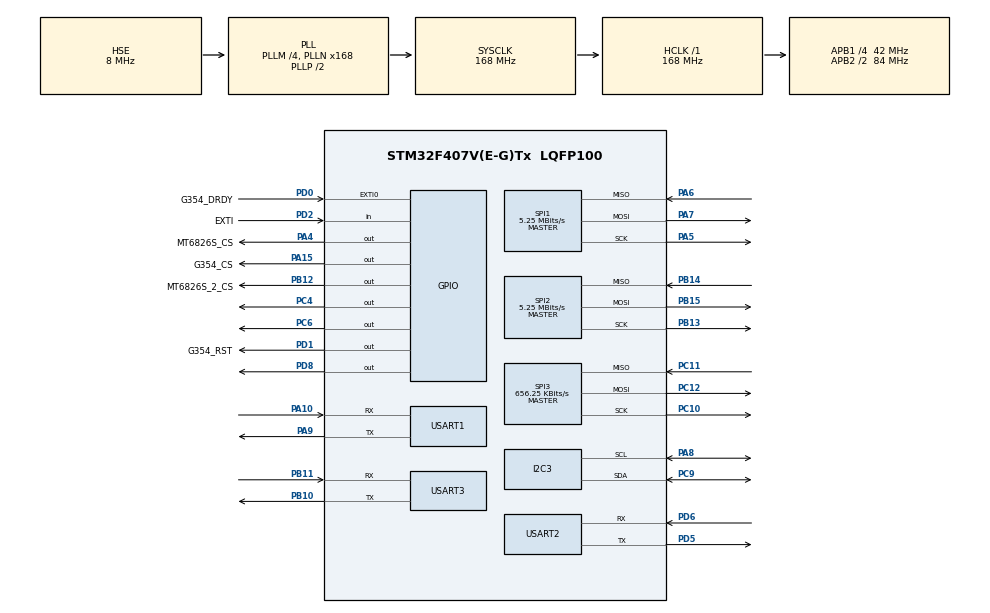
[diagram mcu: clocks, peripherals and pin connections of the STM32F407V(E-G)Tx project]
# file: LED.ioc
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Dma.Request0=SPI1_RX
Dma.Request1=SPI1_TX
Dma.Request2=SPI2_RX
Dma.Request3=SPI2_TX
Dma.Request4=USART2_TX
Dma.SPI1_RX.0.Direction=DMA_PERIPH_TO_MEMORY
Dma.SPI1_RX.0.FIFOMode=DMA_FIFOMODE_DISABLE
Dma.SPI1_RX.0.Instance=DMA2_Stream0
Dma.SPI1_RX.0.MemDataAlignment=DMA_MDATAALIGN_BYTE
Dma.SPI1_RX.0.MemInc=DMA_MINC_ENABLE
Dma.SPI1_RX.0.Mode=DMA_NORMAL
Dma.SPI1_RX.0.PeriphDataAlignment=DMA_PDATAALIGN_BYTE
Dma.SPI1_RX.0.PeriphInc=DMA_PINC_DISABLE
Dma.SPI1_RX.0.Priority=DMA_PRIORITY_HIGH
Dma.SPI1_TX.1.Direction=DMA_MEMORY_TO_PERIPH
Dma.SPI1_TX.1.FIFOMode=DMA_FIFOMODE_DISABLE
Dma.SPI1_TX.1.Instance=DMA2_Stream3
Dma.SPI1_TX.1.MemDataAlignment=DMA_MDATAALIGN_BYTE
Dma.SPI1_TX.1.MemInc=DMA_MINC_ENABLE
Dma.SPI1_TX.1.Mode=DMA_NORMAL
Dma.SPI1_TX.1.PeriphDataAlignment=DMA_PDATAALIGN_BYTE
Dma.SPI1_TX.1.PeriphInc=DMA_PINC_DISABLE
Dma.SPI1_TX.1.Priority=DMA_PRIORITY_HIGH
Dma.SPI2_RX.2.Direction=DMA_PERIPH_TO_MEMORY
Dma.SPI2_RX.2.FIFOMode=DMA_FIFOMODE_DISABLE
Dma.SPI2_RX.2.Instance=DMA1_Stream3
Dma.SPI2_RX.2.MemDataAlignment=DMA_MDATAALIGN_BYTE
Dma.SPI2_RX.2.MemInc=DMA_MINC_ENABLE
Dma.SPI2_RX.2.Mode=DMA_NORMAL
Dma.SPI2_RX.2.PeriphDataAlignment=DMA_PDATAALIGN_BYTE
Dma.SPI2_RX.2.PeriphInc=DMA_PINC_DISABLE
Dma.SPI2_RX.2.Priority=DMA_PRIORITY_HIGH
Dma.SPI2_TX.3.Direction=DMA_MEMORY_TO_PERIPH
Dma.SPI2_TX.3.FIFOMode=DMA_FIFOMODE_DISABLE
Dma.SPI2_TX.3.Instance=DMA1_Stream4
Dma.SPI2_TX.3.MemDataAlignment=DMA_MDATAALIGN_BYTE
Dma.SPI2_TX.3.MemInc=DMA_MINC_ENABLE
Dma.SPI2_TX.3.Mode=DMA_NORMAL
Dma.SPI2_TX.3.PeriphDataAlignment=DMA_PDATAALIGN_BYTE
Dma.SPI2_TX.3.PeriphInc=DMA_PINC_DISABLE
Dma.SPI2_TX.3.Priority=DMA_PRIORITY_HIGH
Dma.USART2_TX.4.Direction=DMA_MEMORY_TO_PERIPH
Dma.USART2_TX.4.FIFOMode=DMA_FIFOMODE_DISABLE
Dma.USART2_TX.4.Instance=DMA1_Stream6
Dma.USART2_TX.4.MemDataAlignment=DMA_MDATAALIGN_BYTE
Dma.USART2_TX.4.MemInc=DMA_MINC_ENABLE
Dma.USART2_TX.4.Mode=DMA_NORMAL
Dma.USART2_TX.4.PeriphDataAlignment=DMA_PDATAALIGN_BYTE
Dma.USART2_TX.4.PeriphInc=DMA_PINC_DISABLE
Dma.USART2_TX.4.Priority=DMA_PRIORITY_MEDIUM
FREERTOS.INCLUDE_uxTaskGetStackHighWaterMark=1
FREERTOS.INCLUDE_vTaskDelayUntil=1
FREERTOS.Tasks01=defaultTask,0,256,StartDefaultTask,Default,NULL,Dynamic,NULL,NULL;imuTask,1,1024,StartimuTask02,Default,NULL,Dynamic,NULL,NULL
FREERTOS.configTOTAL_HEAP_SIZE=20480
Mcu.Family=STM32F4
Mcu.Name=STM32F407V(E-G)Tx
Mcu.Package=LQFP100
NVIC.DMA1_Stream3_IRQn=true\:6\:0\:true\:false\:true\:true\:false\:true\:true
NVIC.DMA1_Stream4_IRQn=true\:6\:0\:true\:false\:true\:true\:false\:true\:true
NVIC.DMA1_Stream6_IRQn=true\:6\:0\:true\:false\:true\:true\:false\:true\:true
NVIC.DMA2_Stream0_IRQn=true\:6\:0\:true\:false\:true\:true\:false\:true\:true
NVIC.DMA2_Stream3_IRQn=true\:6\:0\:true\:false\:true\:true\:false\:true\:true
NVIC.EXTI0_IRQn=true\:5\:0\:false\:false\:true\:true\:true\:true\:true
NVIC.PriorityGroup=NVIC_PRIORITYGROUP_4
NVIC.SPI1_IRQn=true\:5\:0\:false\:false\:true\:true\:true\:true\:true
NVIC.SPI2_IRQn=true\:5\:0\:false\:false\:true\:true\:true\:true\:true
NVIC.TIM6_DAC_IRQn=true\:15\:0\:false\:false\:true\:false\:false\:true\:true
NVIC.TimeBase=TIM6_DAC_IRQn
NVIC.TimeBaseIP=TIM6
NVIC.USART2_IRQn=true\:6\:0\:true\:false\:true\:true\:true\:true\:true
PA10.Mode=Asynchronous
PA10.Signal=USART1_RX
PA13.Mode=Serial_Wire
PA13.Signal=SYS_JTMS-SWDIO
PA14.Mode=Serial_Wire
PA14.Signal=SYS_JTCK-SWCLK
PA15.GPIO_Label=G354_CS
PA15.GPIO_Speed=GPIO_SPEED_FREQ_HIGH
PA15.PinState=GPIO_PIN_SET
PA15.Signal=GPIO_Output
PA4.GPIO_Label=MT6826S_CS
PA4.GPIO_Speed=GPIO_SPEED_FREQ_HIGH
PA4.PinState=GPIO_PIN_SET
PA4.Signal=GPIO_Output
PA5.Mode=Full_Duplex_Master
PA5.Signal=SPI1_SCK
PA6.Mode=Full_Duplex_Master
PA6.Signal=SPI1_MISO
PA7.Mode=Full_Duplex_Master
PA7.Signal=SPI1_MOSI
PA8.Mode=I2C
PA8.Signal=I2C3_SCL
PA9.Mode=Asynchronous
PA9.Signal=USART1_TX
PB10.Mode=Asynchronous
PB10.Signal=USART3_TX
PB11.Mode=Asynchronous
PB11.Signal=USART3_RX
PB12.GPIO_Label=MT6826S_2_CS
PB12.GPIO_Speed=GPIO_SPEED_FREQ_HIGH
PB12.PinState=GPIO_PIN_SET
PB12.Signal=GPIO_Output
PB13.Mode=Full_Duplex_Master
PB13.Signal=SPI2_SCK
PB14.Mode=Full_Duplex_Master
PB14.Signal=SPI2_MISO
PB15.Mode=Full_Duplex_Master
PB15.Signal=SPI2_MOSI
PC10.Mode=Full_Duplex_Master
PC10.Signal=SPI3_SCK
PC11.Mode=Full_Duplex_Master
PC11.Signal=SPI3_MISO
PC12.Mode=Full_Duplex_Master
PC12.Signal=SPI3_MOSI
PC4.Signal=GPIO_Output
PC6.GPIO_PuPd=GPIO_PULLUP
PC6.Signal=GPIO_Output
PC9.Mode=I2C
PC9.Signal=I2C3_SDA
PD0.GPIO_Label=G354_DRDY
PD0.Signal=GPXTI0
PD1.GPIO_Label=G354_RST
PD1.PinState=GPIO_PIN_SET
PD1.Signal=GPIO_Output
PD2.GPIO_Label=EXTI
PD2.Signal=GPIO_Input
PD5.Mode=Asynchronous
PD5.Signal=USART2_TX
PD6.Mode=Asynchronous
PD6.Signal=USART2_RX
PD8.Signal=GPIO_Output
PH0-OSC_IN.Mode=HSE-External-Oscillator
PH0-OSC_IN.Signal=RCC_OSC_IN
PH1-OSC_OUT.Mode=HSE-External-Oscillator
PH1-OSC_OUT.Signal=RCC_OSC_OUT
ProjectManager.HeapSize=0x200
ProjectManager.StackSize=0x400
ProjectManager.TargetToolchain=CMake
RCC.48MHZClocksFreq_Value=84000000
RCC.AHBFreq_Value=168000000
RCC.APB1CLKDivider=RCC_HCLK_DIV4
RCC.APB1Freq_Value=42000000
RCC.APB1TimFreq_Value=84000000
RCC.APB2CLKDivider=RCC_HCLK_DIV2
RCC.APB2Freq_Value=84000000
RCC.APB2TimFreq_Value=168000000
RCC.CortexFreq_Value=168000000
RCC.HCLKFreq_Value=168000000
RCC.HSE_VALUE=8000000
RCC.HSI_VALUE=16000000
RCC.LSE_VALUE=32768
RCC.PLLM=4
RCC.PLLN=168
RCC.PLLSourceVirtual=RCC_PLLSOURCE_HSE
RCC.SYSCLKFreq_VALUE=168000000
RCC.SYSCLKSource=RCC_SYSCLKSOURCE_PLLCLK
RCC.VCOOutputFreq_Value=336000000
SPI1.BaudRatePrescaler=SPI_BAUDRATEPRESCALER_16
SPI1.CLKPhase=SPI_PHASE_2EDGE
SPI1.CLKPolarity=SPI_POLARITY_HIGH
SPI1.CalculateBaudRate=5.25 MBits/s
SPI1.Direction=SPI_DIRECTION_2LINES
SPI1.Mode=SPI_MODE_MASTER
SPI1.VirtualType=VM_MASTER
SPI2.BaudRatePrescaler=SPI_BAUDRATEPRESCALER_8
SPI2.CLKPhase=SPI_PHASE_2EDGE
SPI2.CLKPolarity=SPI_POLARITY_HIGH
SPI2.CalculateBaudRate=5.25 MBits/s
SPI2.Direction=SPI_DIRECTION_2LINES
SPI2.Mode=SPI_MODE_MASTER
SPI2.VirtualType=VM_MASTER
SPI3.BaudRatePrescaler=SPI_BAUDRATEPRESCALER_64
SPI3.CLKPhase=SPI_PHASE_2EDGE
SPI3.CLKPolarity=SPI_POLARITY_HIGH
SPI3.CalculateBaudRate=656.25 KBits/s
SPI3.DataSize=SPI_DATASIZE_16BIT
SPI3.Direction=SPI_DIRECTION_2LINES
SPI3.Mode=SPI_MODE_MASTER
SPI3.VirtualType=VM_MASTER
TIM2.Prescaler=84-1
USART1.VirtualMode=VM_ASYNC
USART2.VirtualMode=VM_ASYNC
USART3.VirtualMode=VM_ASYNC
VP_FREERTOS_VS_CMSIS_V1.Mode=CMSIS_V1
VP_SYS_VS_tim6.Mode=TIM6
VP_TIM2_VS_ClockSourceINT.Mode=Internal
board=custom

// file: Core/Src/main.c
/* USER CODE BEGIN Header */
/**
  ******************************************************************************
  * @file           : main.c
  * @brief          : Main program body
  ******************************************************************************
  * @attention
  *
  * Copyright (c) 2026 STMicroelectronics.
  * All rights reserved.
  *
  * This software is licensed under terms that can be found in the LICENSE file
  * in the root directory of this software component.
  * If no LICENSE file comes with this software, it is provided AS-IS.
  *
  ******************************************************************************
  */
/* USER CODE END Header */
#include "main.h"
#include "cmsis_os.h"

/* USER CODE BEGIN Includes */
#include "imu_app.h"
#include "encoder_app.h"
#include "odometry_app.h"
#include "telemetry_app.h"
#include "display_app.h"
/* USER CODE END Includes */

I2C_HandleTypeDef hi2c3;

SPI_HandleTypeDef hspi1;
SPI_HandleTypeDef hspi2;
SPI_HandleTypeDef hspi3;
DMA_HandleTypeDef hdma_spi1_rx;
DMA_HandleTypeDef hdma_spi1_tx;
DMA_HandleTypeDef hdma_spi2_rx;
DMA_HandleTypeDef hdma_spi2_tx;

TIM_HandleTypeDef htim2;

UART_HandleTypeDef huart1;
UART_HandleTypeDef huart2;
UART_HandleTypeDef huart3;
DMA_HandleTypeDef hdma_usart2_tx;

osThreadId defaultTaskHandle;
osThreadId imuTaskHandle;

void SystemClock_Config(void);
static void MX_GPIO_Init(void);
static void MX_DMA_Init(void);
static void MX_USART1_UART_Init(void);
static void MX_SPI1_Init(void);
static void MX_SPI2_Init(void);
static void MX_SPI3_Init(void);
static void MX_USART2_UART_Init(void);
static void MX_USART3_UART_Init(void);
static void MX_TIM2_Init(void);
static void MX_I2C3_Init(void);
void StartDefaultTask(void const * argument);
void StartimuTask02(void const * argument);

int main(void)
{

  /* MCU Configuration--------------------------------------------------------*/

  /* Reset of all peripherals, Initializes the Flash interface and the Systick. */
  HAL_Init();

  /* Configure the system clock */
  SystemClock_Config();

  /* Initialize all configured peripherals */
  MX_GPIO_Init();
  MX_DMA_Init();
  MX_USART1_UART_Init();
  MX_SPI1_Init();
  MX_SPI2_Init();
  MX_SPI3_Init();
  MX_USART2_UART_Init();
  MX_USART3_UART_Init();
  MX_TIM2_Init();
  MX_I2C3_Init();

  /* Create the thread(s) */
  /* definition and creation of defaultTask */
  osThreadDef(defaultTask, StartDefaultTask, osPriorityNormal, 0, 256);
  defaultTaskHandle = osThreadCreate(osThread(defaultTask), NULL);

  /* definition and creation of imuTask */
  osThreadDef(imuTask, StartimuTask02, osPriorityAboveNormal, 0, 1024);
  imuTaskHandle = osThreadCreate(osThread(imuTask), NULL);

  /* USER CODE BEGIN RTOS_THREADS */
  (void)encoder_app_start(); /* Failures remain visible in g_encoder/g_encoder2.error. */
  (void)odometry_app_start(); /* Coordinates and tracking status: g_odometry. */
  (void)telemetry_app_start(); /* USART2 DMA pose output: g_telemetry. */
  (void)display_app_start(); /* I2C3 OLED：显示 X/Y/Yaw，状态见 g_display。 */
  /* USER CODE END RTOS_THREADS */

  /* Start scheduler */
  osKernelStart();

  /* We should never get here as control is now taken by the scheduler */

  /* Infinite loop */
  while (1)
  {

  }
}

void SystemClock_Config(void)
{
  RCC_OscInitTypeDef RCC_OscInitStruct = {0};
  RCC_ClkInitTypeDef RCC_ClkInitStruct = {0};

  /** Configure the main internal regulator output voltage
  */
  __HAL_RCC_PWR_CLK_ENABLE();
  __HAL_PWR_VOLTAGESCALING_CONFIG(PWR_REGULATOR_VOLTAGE_SCALE1);

  /** Initializes the RCC Oscillators according to the specified parameters
  * in the RCC_OscInitTypeDef structure.
  */
  RCC_OscInitStruct.OscillatorType = RCC_OSCILLATORTYPE_HSE;
  RCC_OscInitStruct.HSEState = RCC_HSE_ON;
  RCC_OscInitStruct.PLL.PLLState = RCC_PLL_ON;
  RCC_OscInitStruct.PLL.PLLSource = RCC_PLLSOURCE_HSE;
  RCC_OscInitStruct.PLL.PLLM = 4;
  RCC_OscInitStruct.PLL.PLLN = 168;
  RCC_OscInitStruct.PLL.PLLP = RCC_PLLP_DIV2;
  RCC_OscInitStruct.PLL.PLLQ = 4;
  if (HAL_RCC_OscConfig(&RCC_OscInitStruct) != HAL_OK)
  {
    Error_Handler();
  }

  /** Initializes the CPU, AHB and APB buses clocks
  */
  RCC_ClkInitStruct.ClockType = RCC_CLOCKTYPE_HCLK|RCC_CLOCKTYPE_SYSCLK
                              |RCC_CLOCKTYPE_PCLK1|RCC_CLOCKTYPE_PCLK2;
  RCC_ClkInitStruct.SYSCLKSource = RCC_SYSCLKSOURCE_PLLCLK;
  RCC_ClkInitStruct.AHBCLKDivider = RCC_SYSCLK_DIV1;
  RCC_ClkInitStruct.APB1CLKDivider = RCC_HCLK_DIV4;
  RCC_ClkInitStruct.APB2CLKDivider = RCC_HCLK_DIV2;

  if (HAL_RCC_ClockConfig(&RCC_ClkInitStruct, FLASH_LATENCY_5) != HAL_OK)
  {
    Error_Handler();
  }
}

static void MX_I2C3_Init(void)
{

  hi2c3.Instance = I2C3;
  hi2c3.Init.ClockSpeed = 100000;
  hi2c3.Init.DutyCycle = I2C_DUTYCYCLE_2;
  hi2c3.Init.OwnAddress1 = 0;
  hi2c3.Init.AddressingMode = I2C_ADDRESSINGMODE_7BIT;
  hi2c3.Init.DualAddressMode = I2C_DUALADDRESS_DISABLE;
  hi2c3.Init.OwnAddress2 = 0;
  hi2c3.Init.GeneralCallMode = I2C_GENERALCALL_DISABLE;
  hi2c3.Init.NoStretchMode = I2C_NOSTRETCH_DISABLE;
  if (HAL_I2C_Init(&hi2c3) != HAL_OK)
  {
    Error_Handler();
  }

}

static void MX_SPI1_Init(void)
{

  /* SPI1 parameter configuration*/
  hspi1.Instance = SPI1;
  hspi1.Init.Mode = SPI_MODE_MASTER;
  hspi1.Init.Direction = SPI_DIRECTION_2LINES;
  hspi1.Init.DataSize = SPI_DATASIZE_8BIT;
  hspi1.Init.CLKPolarity = SPI_POLARITY_HIGH;
  hspi1.Init.CLKPhase = SPI_PHASE_2EDGE;
  hspi1.Init.NSS = SPI_NSS_SOFT;
  hspi1.Init.BaudRatePrescaler = SPI_BAUDRATEPRESCALER_16;
  hspi1.Init.FirstBit = SPI_FIRSTBIT_MSB;
  hspi1.Init.TIMode = SPI_TIMODE_DISABLE;
  hspi1.Init.CRCCalculation = SPI_CRCCALCULATION_DISABLE;
  hspi1.Init.CRCPolynomial = 10;
  if (HAL_SPI_Init(&hspi1) != HAL_OK)
  {
    Error_Handler();
  }

}

static void MX_SPI2_Init(void)
{

  /* SPI2 parameter configuration*/
  hspi2.Instance = SPI2;
  hspi2.Init.Mode = SPI_MODE_MASTER;
  hspi2.Init.Direction = SPI_DIRECTION_2LINES;
  hspi2.Init.DataSize = SPI_DATASIZE_8BIT;
  hspi2.Init.CLKPolarity = SPI_POLARITY_HIGH;
  hspi2.Init.CLKPhase = SPI_PHASE_2EDGE;
  hspi2.Init.NSS = SPI_NSS_SOFT;
  hspi2.Init.BaudRatePrescaler = SPI_BAUDRATEPRESCALER_8;
  hspi2.Init.FirstBit = SPI_FIRSTBIT_MSB;
  hspi2.Init.TIMode = SPI_TIMODE_DISABLE;
  hspi2.Init.CRCCalculation = SPI_CRCCALCULATION_DISABLE;
  hspi2.Init.CRCPolynomial = 10;
  if (HAL_SPI_Init(&hspi2) != HAL_OK)
  {
    Error_Handler();
  }

}

static void MX_SPI3_Init(void)
{

  /* SPI3 parameter configuration*/
  hspi3.Instance = SPI3;
  hspi3.Init.Mode = SPI_MODE_MASTER;
  hspi3.Init.Direction = SPI_DIRECTION_2LINES;
  hspi3.Init.DataSize = SPI_DATASIZE_16BIT;
  hspi3.Init.CLKPolarity = SPI_POLARITY_HIGH;
  hspi3.Init.CLKPhase = SPI_PHASE_2EDGE;
  hspi3.Init.NSS = SPI_NSS_SOFT;
  hspi3.Init.BaudRatePrescaler = SPI_BAUDRATEPRESCALER_64;
  hspi3.Init.FirstBit = SPI_FIRSTBIT_MSB;
  hspi3.Init.TIMode = SPI_TIMODE_DISABLE;
  hspi3.Init.CRCCalculation = SPI_CRCCALCULATION_DISABLE;
  hspi3.Init.CRCPolynomial = 10;
  if (HAL_SPI_Init(&hspi3) != HAL_OK)
  {
    Error_Handler();
  }

}

static void MX_TIM2_Init(void)
{

  TIM_ClockConfigTypeDef sClockSourceConfig = {0};
  TIM_MasterConfigTypeDef sMasterConfig = {0};

  htim2.Instance = TIM2;
  htim2.Init.Prescaler = 84-1;
  htim2.Init.CounterMode = TIM_COUNTERMODE_UP;
  htim2.Init.Period = 4294967295;
  htim2.Init.ClockDivision = TIM_CLOCKDIVISION_DIV1;
  htim2.Init.AutoReloadPreload = TIM_AUTORELOAD_PRELOAD_DISABLE;
  if (HAL_TIM_Base_Init(&htim2) != HAL_OK)
  {
    Error_Handler();
  }
  sClockSourceConfig.ClockSource = TIM_CLOCKSOURCE_INTERNAL;
  if (HAL_TIM_ConfigClockSource(&htim2, &sClockSourceConfig) != HAL_OK)
  {
    Error_Handler();
  }
  sMasterConfig.MasterOutputTrigger = TIM_TRGO_RESET;
  sMasterConfig.MasterSlaveMode = TIM_MASTERSLAVEMODE_DISABLE;
  if (HAL_TIMEx_MasterConfigSynchronization(&htim2, &sMasterConfig) != HAL_OK)
  {
    Error_Handler();
  }

}

static void MX_USART1_UART_Init(void)
{

  huart1.Instance = USART1;
  huart1.Init.BaudRate = 115200;
  huart1.Init.WordLength = UART_WORDLENGTH_8B;
  huart1.Init.StopBits = UART_STOPBITS_1;
  huart1.Init.Parity = UART_PARITY_NONE;
  huart1.Init.Mode = UART_MODE_TX_RX;
  huart1.Init.HwFlowCtl = UART_HWCONTROL_NONE;
  huart1.Init.OverSampling = UART_OVERSAMPLING_16;
  if (HAL_UART_Init(&huart1) != HAL_OK)
  {
    Error_Handler();
  }

}

static void MX_USART2_UART_Init(void)
{

  huart2.Instance = USART2;
  huart2.Init.BaudRate = 115200;
  huart2.Init.WordLength = UART_WORDLENGTH_8B;
  huart2.Init.StopBits = UART_STOPBITS_1;
  huart2.Init.Parity = UART_PARITY_NONE;
  huart2.Init.Mode = UART_MODE_TX_RX;
  huart2.Init.HwFlowCtl = UART_HWCONTROL_NONE;
  huart2.Init.OverSampling = UART_OVERSAMPLING_16;
  if (HAL_UART_Init(&huart2) != HAL_OK)
  {
    Error_Handler();
  }

}

static void MX_USART3_UART_Init(void)
{

  huart3.Instance = USART3;
  huart3.Init.BaudRate = 115200;
  huart3.Init.WordLength = UART_WORDLENGTH_8B;
  huart3.Init.StopBits = UART_STOPBITS_1;
  huart3.Init.Parity = UART_PARITY_NONE;
  huart3.Init.Mode = UART_MODE_TX_RX;
  huart3.Init.HwFlowCtl = UART_HWCONTROL_NONE;
  huart3.Init.OverSampling = UART_OVERSAMPLING_16;
  if (HAL_UART_Init(&huart3) != HAL_OK)
  {
    Error_Handler();
  }

}

static void MX_DMA_Init(void)
{

  /* DMA controller clock enable */
  __HAL_RCC_DMA2_CLK_ENABLE();
  __HAL_RCC_DMA1_CLK_ENABLE();

  /* DMA interrupt init */
  /* DMA1_Stream3_IRQn interrupt configuration */
  HAL_NVIC_SetPriority(DMA1_Stream3_IRQn, 6, 0);
  HAL_NVIC_EnableIRQ(DMA1_Stream3_IRQn);
  /* DMA1_Stream4_IRQn interrupt configuration */
  HAL_NVIC_SetPriority(DMA1_Stream4_IRQn, 6, 0);
  HAL_NVIC_EnableIRQ(DMA1_Stream4_IRQn);
  /* DMA1_Stream6_IRQn interrupt configuration */
  HAL_NVIC_SetPriority(DMA1_Stream6_IRQn, 6, 0);
  HAL_NVIC_EnableIRQ(DMA1_Stream6_IRQn);
  /* DMA2_Stream0_IRQn interrupt configuration */
  HAL_NVIC_SetPriority(DMA2_Stream0_IRQn, 6, 0);
  HAL_NVIC_EnableIRQ(DMA2_Stream0_IRQn);
  /* DMA2_Stream3_IRQn interrupt configuration */
  HAL_NVIC_SetPriority(DMA2_Stream3_IRQn, 6, 0);
  HAL_NVIC_EnableIRQ(DMA2_Stream3_IRQn);

}

static void MX_GPIO_Init(void)
{
  GPIO_InitTypeDef GPIO_InitStruct = {0};

  /* GPIO Ports Clock Enable */
  __HAL_RCC_GPIOH_CLK_ENABLE();
  __HAL_RCC_GPIOA_CLK_ENABLE();
  __HAL_RCC_GPIOC_CLK_ENABLE();
  __HAL_RCC_GPIOB_CLK_ENABLE();
  __HAL_RCC_GPIOD_CLK_ENABLE();

  /*Configure GPIO pin Output Level */
  HAL_GPIO_WritePin(GPIOA, MT6826S_CS_Pin|G354_CS_Pin, GPIO_PIN_SET);

  /*Configure GPIO pin Output Level */
  HAL_GPIO_WritePin(GPIOC, GPIO_PIN_4|GPIO_PIN_6, GPIO_PIN_RESET);

  /*Configure GPIO pin Output Level */
  HAL_GPIO_WritePin(MT6826S_2_CS_GPIO_Port, MT6826S_2_CS_Pin, GPIO_PIN_SET);

  /*Configure GPIO pin Output Level */
  HAL_GPIO_WritePin(GPIOD, GPIO_PIN_8, GPIO_PIN_RESET);

  /*Configure GPIO pin Output Level */
  HAL_GPIO_WritePin(G354_RST_GPIO_Port, G354_RST_Pin, GPIO_PIN_SET);

  /*Configure GPIO pins : MT6826S_CS_Pin G354_CS_Pin */
  GPIO_InitStruct.Pin = MT6826S_CS_Pin|G354_CS_Pin;
  GPIO_InitStruct.Mode = GPIO_MODE_OUTPUT_PP;
  GPIO_InitStruct.Pull = GPIO_NOPULL;
  GPIO_InitStruct.Speed = GPIO_SPEED_FREQ_HIGH;
  HAL_GPIO_Init(GPIOA, &GPIO_InitStruct);

  /*Configure GPIO pin : PC4 */
  GPIO_InitStruct.Pin = GPIO_PIN_4;
  GPIO_InitStruct.Mode = GPIO_MODE_OUTPUT_PP;
  GPIO_InitStruct.Pull = GPIO_NOPULL;
  GPIO_InitStruct.Speed = GPIO_SPEED_FREQ_LOW;
  HAL_GPIO_Init(GPIOC, &GPIO_InitStruct);

  /*Configure GPIO pin : MT6826S_2_CS_Pin */
  GPIO_InitStruct.Pin = MT6826S_2_CS_Pin;
  GPIO_InitStruct.Mode = GPIO_MODE_OUTPUT_PP;
  GPIO_InitStruct.Pull = GPIO_NOPULL;
  GPIO_InitStruct.Speed = GPIO_SPEED_FREQ_HIGH;
  HAL_GPIO_Init(MT6826S_2_CS_GPIO_Port, &GPIO_InitStruct);

  /*Configure GPIO pins : PD8 G354_RST_Pin */
  GPIO_InitStruct.Pin = GPIO_PIN_8|G354_RST_Pin;
  GPIO_InitStruct.Mode = GPIO_MODE_OUTPUT_PP;
  GPIO_InitStruct.Pull = GPIO_NOPULL;
  GPIO_InitStruct.Speed = GPIO_SPEED_FREQ_LOW;
  HAL_GPIO_Init(GPIOD, &GPIO_InitStruct);

  /*Configure GPIO pin : PC6 */
  GPIO_InitStruct.Pin = GPIO_PIN_6;
  GPIO_InitStruct.Mode = GPIO_MODE_OUTPUT_PP;
  GPIO_InitStruct.Pull = GPIO_PULLUP;
  GPIO_InitStruct.Speed = GPIO_SPEED_FREQ_LOW;
  HAL_GPIO_Init(GPIOC, &GPIO_InitStruct);

  /*Configure GPIO pin : G354_DRDY_Pin */
  GPIO_InitStruct.Pin = G354_DRDY_Pin;
  GPIO_InitStruct.Mode = GPIO_MODE_IT_RISING;
  GPIO_InitStruct.Pull = GPIO_NOPULL;
  HAL_GPIO_Init(G354_DRDY_GPIO_Port, &GPIO_InitStruct);

  /*Configure GPIO pin : EXTI_Pin */
  GPIO_InitStruct.Pin = EXTI_Pin;
  GPIO_InitStruct.Mode = GPIO_MODE_INPUT;
  GPIO_InitStruct.Pull = GPIO_NOPULL;
  HAL_GPIO_Init(EXTI_GPIO_Port, &GPIO_InitStruct);

  /* EXTI interrupt init*/
  HAL_NVIC_SetPriority(EXTI0_IRQn, 5, 0);
  HAL_NVIC_EnableIRQ(EXTI0_IRQn);

}

void StartDefaultTask(void const * argument)
{
  for(;;)
  {
    osDelay(1);
  }
}

void StartimuTask02(void const * argument)
{
  /* USER CODE BEGIN StartimuTask02 */
  (void)argument;
  imu_app_task();
  /* USER CODE END StartimuTask02 */
}

void HAL_TIM_PeriodElapsedCallback(TIM_HandleTypeDef *htim)
{
  if (htim->Instance == TIM6)
  {
    HAL_IncTick();
  }
}

void Error_Handler(void)
{
  __disable_irq();
  while (1)
  {
  }
}
